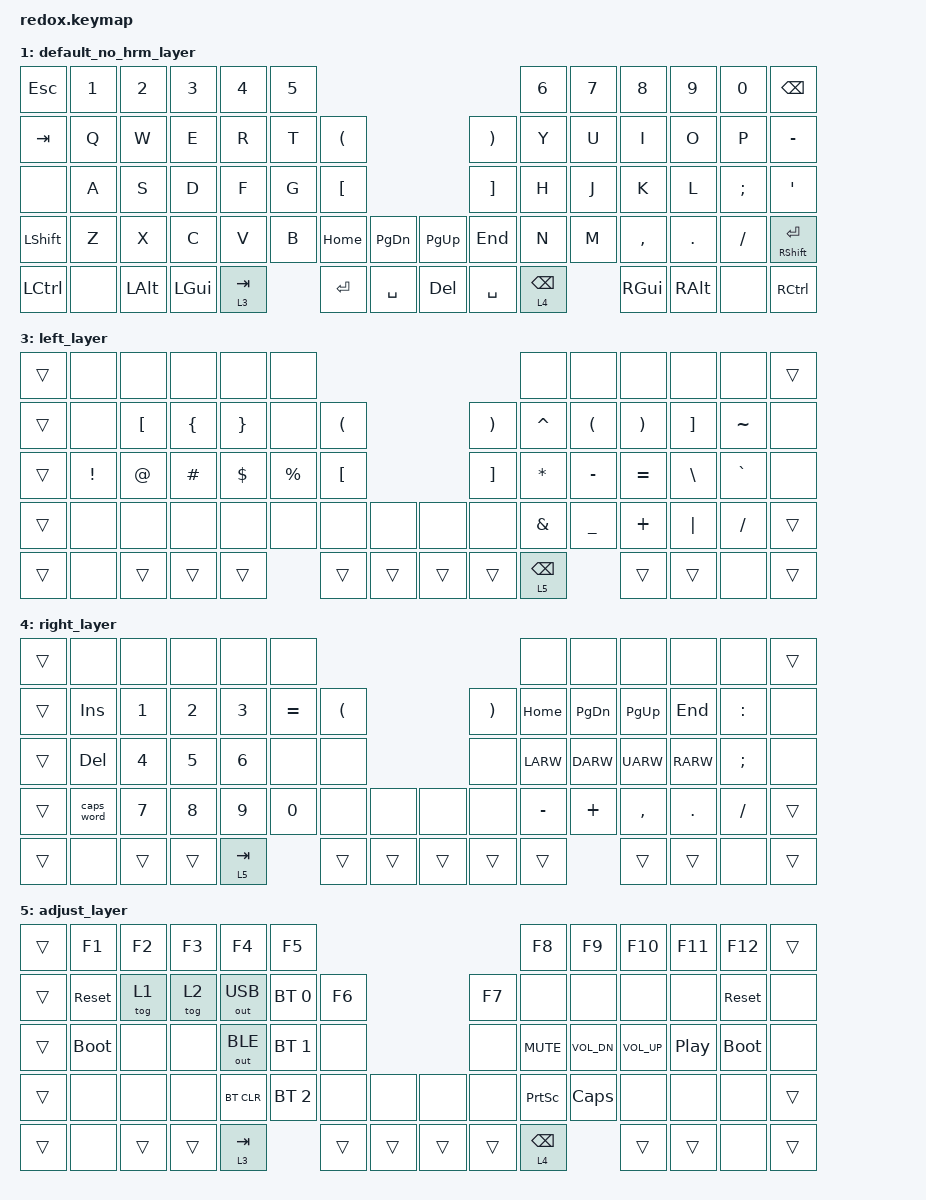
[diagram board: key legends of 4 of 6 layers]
/*
 * Copyright (c) 2021 The ZMK Contributors
 *
 * SPDX-License-Identifier: MIT
 */

#include <behaviors.dtsi>
#include <dt-bindings/zmk/keys.h>
#include <dt-bindings/zmk/bt.h>
#include <dt-bindings/zmk/ext_power.h>
#include <dt-bindings/zmk/outputs.h>

// Home row mods macro
#define HRML(k1,k2,k3,k4) &ht LSHFT k1 &ht LALT k2 &ht LCTRL k3 &ht LGUI k4
#define HRMR(k1,k2,k3,k4) &ht RGUI k1 &ht RCTRL k2 &ht RALT k3 &ht RSHFT k4

/ {
    behaviors {
        ht: hold_tap {
            label = "hold_tap";
            compatible = "zmk,behavior-hold-tap";
            #binding-cells = <2>;
            flavor = "tap-preferred";
            tapping-term-ms = <220>;
            quick-tap-ms = <150>;
            global-quick-tap;
            bindings = <&kp>, <&kp>;
        };
    };

    keymap {
        compatible =  "zmk,keymap" ;

// Layer 0
        default_layer {
        bindings = <
//        ╭──────────┬──────────┬──────────┬──────────┬──────────┬──────────╮                                               ╭──────────┬──────────┬──────────┬──────────┬──────────┬──────────╮
            &kp ESC    &kp N1     &kp N2     &kp N3     &kp N4     &kp N5                                                     &kp N6     &kp N7     &kp N8     &kp N9     &kp N0     &kp BSPC
//        │ ESC      │ 1 !      │ 2 @      │ 3 #      │ 4 $      │ 5 %      ├──────────╮                         ╭──────────┤ 6 ^      │ 7 &      │ 8 *      │ 9 (      │ 0 )      │ BSPC     │
//        ├──────────┼──────────┼──────────┼──────────┼──────────┼──────────┤ (        │                         │ )        ├──────────┼──────────┼──────────├──────────┼──────────┼──────────┤
            &kp TAB    &kp Q      &kp W      &kp E      &kp R      &kp T      &kp LPAR                             &kp RPAR   &kp Y      &kp U      &kp I      &kp O      &kp P      &kp MINUS
//        │ TAB      │ Q        │ W        │ E        │ R        │ T        ├──────────┤                         ├──────────┤ Y        │ U        │ I        │ O        │ P        │ - _      │
//        ├──────────┼──────────┼──────────┼──────────┼──────────┼──────────┤          │                         │          ├──────────┼──────────┼──────────├──────────┼──────────┼──────────┤
            &none      HRML(A,    S,         D,         F)         &kp G      &kp LBKT                             &kp RBKT   &kp H      HRMR(J,    K,         L,         SEMI)      &kp SQT
//        │          │ A        │ S        │ D        │ F        │ G        │ [ {      │                         │ ] }      │ H        │ J        │ K        │ L        │ ; :      │ ' "      │
//        ├──────────┼──────────┼──────────┼──────────┼──────────┼──────────┼──────────┼──────────╮   ╭──────────┼──────────┼──────────┼──────────┼──────────├──────────┼──────────┼──────────┤
            &kp LSHFT  &kp Z      &kp X      &kp C      &kp V      &kp B      &kp HOME   &kp PG_DN      &kp PG_UP  &kp END    &kp N      &kp M      &kp COMMA  &kp DOT    &kp FSLH   &mt RSHFT RET
//        │ SHIFT    │ Z        │ X        │ C        │ V        │ B        │ HOME     │ PG_DOWN  │   │ PG_UP    │ END      │ N        │ M        │ , <      │ . >      │ / ?      │SHIFT(RET)│
//        ├──────────┼──────────┼──────────┼──────────┼──────────┴──────────┼──────────┼──────────┤   ├──────────┼──────────┼──────────┴──────────┼──────────├──────────┼──────────┼──────────┤
            &kp LCTRL  &none      &kp LALT   &kp LGUI   &lt 3 TAB             &kp ENTER  &kp SPACE      &kp DEL    &kp SPACE  &lt 4 BSPC            &kp RGUI   &kp RALT   &none      &kp RCTRL
//        │ CRTL     │          │ ALT      │ GUI      │ LEFT(TAB)           │ ENTER    │ SPACE    │   │ DEL      │ SPACE    │ RIGHT(BSPC)         │ GUI      │ ALT      │          │ CTRL     │
//        ╰──────────┴──────────┴──────────┴──────────┴─────────────────────┤          │          │   │          │          ├─────────────────────┴──────────┴──────────┴──────────┴──────────╯
//                                                                          ╰──────────┴──────────╯   ╰──────────┴──────────╯
            >;

        };

// Layer 1
        // it's a copy of default layer but without HRML and HRMR home row modifiers macros
        default_no_hrm_layer {
        bindings = <
//        ╭──────────┬──────────┬──────────┬──────────┬──────────┬──────────╮                                               ╭──────────┬──────────┬──────────┬──────────┬──────────┬──────────╮
            &kp ESC    &kp N1     &kp N2     &kp N3     &kp N4     &kp N5                                                     &kp N6     &kp N7     &kp N8     &kp N9     &kp N0     &kp BSPC
//        │ ESC      │ 1 !      │ 2 @      │ 3 #      │ 4 $      │ 5 %      ├──────────╮                         ╭──────────┤ 6 ^      │ 7 &      │ 8 *      │ 9 (      │ 0 )      │ BSPC     │
//        ├──────────┼──────────┼──────────┼──────────┼──────────┼──────────┤ (        │                         │ )        ├──────────┼──────────┼──────────├──────────┼──────────┼──────────┤
            &kp TAB    &kp Q      &kp W      &kp E      &kp R      &kp T      &kp LPAR                             &kp RPAR   &kp Y      &kp U      &kp I      &kp O      &kp P      &kp MINUS
//        │ TAB      │ Q        │ W        │ E        │ R        │ T        ├──────────┤                         ├──────────┤ Y        │ U        │ I        │ O        │ P        │ - _      │
//        ├──────────┼──────────┼──────────┼──────────┼──────────┼──────────┤          │                         │          ├──────────┼──────────┼──────────├──────────┼──────────┼──────────┤
            &none      &kp A      &kp S      &kp D      &kp F      &kp G      &kp LBKT                             &kp RBKT   &kp H      &kp J      &kp K      &kp L      &kp SEMI   &kp SQT
//        │          │ A        │ S        │ D        │ F        │ G        │ [ {      │                         │ ] }      │ H        │ J        │ K        │ L        │ ; :      │ ' "      │
//        ├──────────┼──────────┼──────────┼──────────┼──────────┼──────────┼──────────┼──────────╮   ╭──────────┼──────────┼──────────┼──────────┼──────────├──────────┼──────────┼──────────┤
            &kp LSHFT  &kp Z      &kp X      &kp C      &kp V      &kp B      &kp HOME   &kp PG_DN      &kp PG_UP  &kp END    &kp N      &kp M      &kp COMMA  &kp DOT    &kp FSLH   &mt RSHFT RET
//        │ SHIFT    │ Z        │ X        │ C        │ V        │ B        │ HOME     │ PG_DOWN  │   │ PG_UP    │ END      │ N        │ M        │ , <      │ . >      │ / ?      │SHIFT(RET)│
//        ├──────────┼──────────┼──────────┼──────────┼──────────┴──────────┼──────────┼──────────┤   ├──────────┼──────────┼──────────┴──────────┼──────────├──────────┼──────────┼──────────┤
            &kp LCTRL  &none      &kp LALT   &kp LGUI   &lt 3 TAB             &kp ENTER  &kp SPACE      &kp DEL    &kp SPACE  &lt 4 BSPC            &kp RGUI   &kp RALT   &none      &kp RCTRL
//        │ CRTL     │          │ ALT      │ GUI      │ LEFT(TAB)           │ ENTER    │ SPACE    │   │ DEL      │ SPACE    │ RIGHT(BSPC)         │ GUI      │ ALT      │          │ CTRL     │
//        ╰──────────┴──────────┴──────────┴──────────┴─────────────────────┤          │          │   │          │          ├─────────────────────┴──────────┴──────────┴──────────┴──────────╯
//                                                                          ╰──────────┴──────────╯   ╰──────────┴──────────╯
            >;
        };

// Layer 2
        // it's a colemak mod dh layout with home row modifiers
        default_colemak_dh_layer {
        bindings = <
//        ╭──────────┬──────────┬──────────┬──────────┬──────────┬──────────╮                                               ╭──────────┬──────────┬──────────┬──────────┬──────────┬──────────╮
            &kp ESC    &kp N1     &kp N2     &kp N3     &kp N4     &kp N5                                                     &kp N6     &kp N7     &kp N8     &kp N9     &kp N0     &kp BSPC
//        │ ESC      │ 1 !      │ 2 @      │ 3 #      │ 4 $      │ 5 %      ├──────────╮                         ╭──────────┤ 6 ^      │ 7 &      │ 8 *      │ 9 (      │ 0 )      │ BSPC     │
//        ├──────────┼──────────┼──────────┼──────────┼──────────┼──────────┤ (        │                         │ )        ├──────────┼──────────┼──────────├──────────┼──────────┼──────────┤
            &kp TAB    &kp Q      &kp W      &kp F      &kp P      &kp B      &kp LPAR                             &kp RPAR   &kp J      &kp L      &kp U      &kp Y      &kp SEMI   &kp MINUS
//        │ TAB      │ Q        │ W        │ F        │ P        │ B        ├──────────┤                         ├──────────┤ J        │ L        │ U        │ Y        │ ; :      │ - _      │
//        ├──────────┼──────────┼──────────┼──────────┼──────────┼──────────┤          │                         │          ├──────────┼──────────┼──────────├──────────┼──────────┼──────────┤
            &none      HRML(A,    R,         S,         T)         &kp G      &kp LBKT                             &kp RBKT   &kp M      HRMR(N,    E,         I,         O)         &kp SQT
//        │          │ A        │ R        │ S        │ T        │ G        │ [ {      │                         │ ] }      │ M        │ N        │ E        │ I        │ O        │ ' "      │
//        ├──────────┼──────────┼──────────┼──────────┼──────────┼──────────┼──────────┼──────────╮   ╭──────────┼──────────┼──────────┼──────────┼──────────├──────────┼──────────┼──────────┤
            &kp LSHFT  &kp Z      &kp X      &kp C      &kp D      &kp V      &kp HOME   &kp PG_DN      &kp PG_UP  &kp END    &kp K      &kp H      &kp COMMA  &kp DOT    &kp FSLH   &mt RSHFT RET
//        │ SHIFT    │ Z        │ X        │ C        │ D        │ V        │ HOME     │ PG_DOWN  │   │ PG_UP    │ END      │ K        │ H        │ , <      │ . >      │ / ?      │SHIFT(RET)│
//        ├──────────┼──────────┼──────────┼──────────┼──────────┴──────────┼──────────┼──────────┤   ├──────────┼──────────┼──────────┴──────────┼──────────├──────────┼──────────┼──────────┤
            &kp LCTRL  &none      &kp LALT   &kp LGUI   &lt 3 TAB             &kp ENTER  &kp SPACE      &kp DEL    &kp SPACE  &lt 4 BSPC            &kp RGUI   &kp RALT   &none      &kp RCTRL
//        │ CRTL     │          │ ALT      │ GUI      │ LEFT(TAB)           │ ENTER    │ SPACE    │   │ DEL      │ SPACE    │ RIGHT(BSPC)         │ GUI      │ ALT      │          │ CTRL     │
//        ╰──────────┴──────────┴──────────┴──────────┴─────────────────────┤          │          │   │          │          ├─────────────────────┴──────────┴──────────┴──────────┴──────────╯
//                                                                          ╰──────────┴──────────╯   ╰──────────┴──────────╯
            >;
        };

// Layer 3
        left_layer {
        bindings = <
//        ╭──────────┬──────────┬──────────┬──────────┬──────────┬──────────╮                                               ╭──────────┬──────────┬──────────┬──────────┬──────────┬──────────╮
            &trans     &none      &none      &none      &none      &none                                                      &none      &none      &none      &none      &none      &trans
//        │ ESC      │          │          │          │          │          ├──────────╮                         ╭──────────┤          │          │          │          │          │ BSPC     │
//        ├──────────┼──────────┼──────────┼──────────┼──────────┼──────────┤ (        │                         │ )        ├──────────┼──────────┼──────────├──────────┼──────────┼──────────┤
            &trans     &none      &kp LBKT   &kp LBRC   &kp RBRC   &none      &kp LPAR                             &kp RPAR   &kp CARET  &kp LPAR   &kp RPAR   &kp RBKT   &kp TILDE  &none
//        │ TAB      │          │ [ {      │ {        │ }        │          ├──────────┤                         ├──────────┤ ^        │ (        │ )        │ ] }      │ ~        │          │
//        ├──────────┼──────────┼──────────┼──────────┼──────────┼──────────┤          │                         │          ├──────────┼──────────┼──────────├──────────┼──────────┼──────────┤
            &trans     &kp EXCL   &kp AT     &kp HASH   &kp DLLR   &kp PRCNT  &kp LBKT                             &kp RBKT   &kp ASTRK  &kp MINUS  &kp EQUAL  &kp BSLH   &kp GRAVE  &none
//        │          │ !        │ @        │ #        │ $        │ %        │ [ {      │                         │ ] }      │ *        │ - _      │ = +      │ \ |      │ ` ~      │          │
//        ├──────────┼──────────┼──────────┼──────────┼──────────┼──────────┼──────────┼──────────╮   ╭──────────┼──────────┼──────────┼──────────┼──────────├──────────┼──────────┼──────────┤
            &trans     &none      &none      &none      &none      &none      &none      &none          &none      &none      &kp AMPS   &kp UNDER  &kp PLUS   &kp PIPE   &kp FSLH    &trans
//        │ SHIFT    │          │          │          │          │          │          │          │   │          │          │ &        │ _        │ +        │ |        │ / ?      │SHIFT(RET)│
//        ├──────────┼──────────┼──────────┼──────────┼──────────┴──────────┼──────────┼──────────┤   ├──────────┼──────────┼──────────┴──────────┼──────────├──────────┼──────────┼──────────┤
            &trans     &none      &trans     &trans     &trans                &trans     &trans         &trans     &trans     &lt 5 BSPC            &trans     &trans     &none      &trans
//        │ CRTL     │          │ ALT      │ GUI      │ LEFT(TAB)           │ ENTER    │ SPACE    │   │ DEL      │ SPACE    │ ADJUST(BSPC)        │ GUI      │ ALT      │          │ CTRL     │
//        ╰──────────┴──────────┴──────────┴──────────┴─────────────────────┤          │          │   │          │          ├─────────────────────┴──────────┴──────────┴──────────┴──────────╯
//                                                                          ╰──────────┴──────────╯   ╰──────────┴──────────╯
            >;
        };

// Layer 4
        right_layer {
        bindings = <
//        ╭──────────┬──────────┬──────────┬──────────┬──────────┬──────────╮                                               ╭──────────┬──────────┬──────────┬──────────┬──────────┬──────────╮
            &trans     &none      &none      &none      &none      &none                                                      &none      &none      &none      &none      &none      &trans
//        │ ESC      │          │          │          │          │          ├──────────╮                         ╭──────────┤          │          │          │          │          │ BSPC     │
//        ├──────────┼──────────┼──────────┼──────────┼──────────┼──────────┤ (        │                         │ )        ├──────────┼──────────┼──────────├──────────┼──────────┼──────────┤
            &trans     &kp INS    &kp N1     &kp N2     &kp N3     &kp EQUAL  &kp LPAR                             &kp RPAR   &kp HOME   &kp PG_DN  &kp PG_UP  &kp END    &kp COLON  &none
//        │ TAB      │ INSERT   │ 1 !      │ 2 @      │ 3 #      │ = +      ├──────────┤                         ├──────────┤ HOME     │ PGDN     │ PGUP     │ END      │ :        │          │
//        ├──────────┼──────────┼──────────┼──────────┼──────────┼──────────┤          │                         │          ├──────────┼──────────┼──────────├──────────┼──────────┼──────────┤
            &trans     &kp DEL    &kp N4     &kp N5     &kp N6     &none      &none                                &none      &kp LARW   &kp DARW   &kp UARW   &kp RARW   &kp SEMI   &none
//        │          │ DEL      │ 4 $      │ 5 %      │ 6 ^      │          │          │                         │          │ LEFT     │ DOWN     │ UP       │ RIGHT    │ ; :      │          │
//        ├──────────┼──────────┼──────────┼──────────┼──────────┼──────────┼──────────┼──────────╮   ╭──────────┼──────────┼──────────┼──────────┼──────────├──────────┼──────────┼──────────┤
            &trans     &caps_word &kp N7     &kp N8     &kp N9     &kp N0     &none      &none          &none      &none      &kp MINUS  &kp PLUS   &kp COMMA  &kp DOT    &kp FSLH   &trans
//        │ SHIFT    │ CAPS     │ 7 &      │ 8 *      │ 9 (      │ 0 )      │          │          │   │          │          │ - _      │ +        │ , <      │ . >      │ / ?      │SHIFT(RET)│
//        ├──────────┼──────────┼──────────┼──────────┼──────────┴──────────┼──────────┼──────────┤   ├──────────┼──────────┼──────────┴──────────┼──────────├──────────┼──────────┼──────────┤
            &trans     &none      &trans     &trans     &lt 5 TAB             &trans     &trans         &trans     &trans     &trans                &trans     &trans     &none      &trans
//        │ CRTL     │          │ ALT      │ GUI      │ ADJUST(TAB)         │ ENTER    │ SPACE    │   │ DEL      │ SPACE    │ RIGHT(BSPC)         │ GUI      │ ALT      │          │ CTRL     │
//        ╰──────────┴──────────┴──────────┴──────────┴─────────────────────┤          │          │   │          │          ├─────────────────────┴──────────┴──────────┴──────────┴──────────╯
//                                                                          ╰──────────┴──────────╯   ╰──────────┴──────────╯
            >;
        };

// Layer 5
        adjust_layer {
        bindings = <
//        ╭──────────┬──────────┬──────────┬──────────┬──────────┬──────────╮                                               ╭──────────┬──────────┬──────────┬──────────┬──────────┬──────────╮
            &trans     &kp F1     &kp F2     &kp F3     &kp F4     &kp F5                                                     &kp F8     &kp F9     &kp F10    &kp F11    &kp F12    &trans
//        │ ESC      │ F1       │ F2       │ F3       │ F4       │ F5       ├──────────╮                         ╭──────────┤ F8       │ F9       │ F10      │ F11      │ F12      │ BSPC     │
//        ├──────────┼──────────┼──────────┼──────────┼──────────┼──────────┤ F6       │                         │ F7       ├──────────┼──────────┼──────────├──────────┼──────────┼──────────┤
            &trans     &sys_reset &tog 1     &tog 2  &out OUT_USB &bt BT_SEL 0 &kp F6                               &kp F7     &none      &none      &none      &none     &sys_reset &none
//        │ TAB      │ RESET    │ HRM TGL  │ COLE TGL │ OUT USB  │ BT 0     ├──────────┤                         ├──────────┤          │          │          │          │ RESET    │          │
//        ├──────────┼──────────┼──────────┼──────────┼──────────┼──────────┤          │                         │          ├──────────┼──────────┼──────────├──────────┼──────────┼──────────┤
            &trans    &bootloader &none      &none &out OUT_BLE &bt BT_SEL 1 &none                                 &none    &kp K_MUTE &kp C_VOL_DN &kp C_VOL_UP &kp C_PLAY_PAUSE &bootloader &none
//        │          │BOOTLOADER│          │          │ OUT BT   │ BT 1     │          │                         │          │ MUTE     │ VOL DN   │ VOL UP   │PLAY/PAUSE│BOOTLOADER│          │
//        ├──────────┼──────────┼──────────┼──────────┼──────────┼──────────┼──────────┼──────────╮   ╭──────────┼──────────┼──────────┼──────────┼──────────├──────────┼──────────┼──────────┤
            &trans     &none      &none      &none     &bt BT_CLR &bt BT_SEL 2 &none     &none          &none      &none      &kp PSCRN  &kp CLCK   &none      &none      &none      &trans
//        │ SHIFT    │          │          │          │ BT CLR   │ BT 2     │          │          │   │          │          │ PSCRN    │ CLCK     │          │          │          │SHIFT(RET)│
//        ├──────────┼──────────┼──────────┼──────────┼──────────┴──────────┼──────────┼──────────┤   ├──────────┼──────────┼──────────┴──────────┼──────────├──────────┼──────────┼──────────┤
            &trans     &none      &trans     &trans     &lt 3 TAB             &trans     &trans         &trans     &trans     &lt 4 BSPC            &trans     &trans     &none      &trans
//        │ CRTL     │          │ ALT      │ GUI      │ LEFT(TAB)           │ ENTER    │ SPACE    │   │ DEL      │ SPACE    │ RIGHT(BSPC)         │ GUI      │ ALT      │          │ CTRL     │
//        ╰──────────┴──────────┴──────────┴──────────┴─────────────────────┤          │          │   │          │          ├─────────────────────┴──────────┴──────────┴──────────┴──────────╯
//                                                                          ╰──────────┴──────────╯   ╰──────────┴──────────╯
            >;
        };
    };
};
